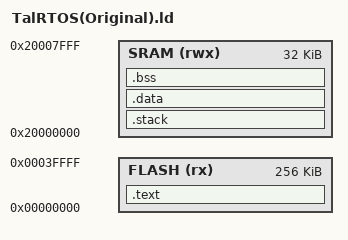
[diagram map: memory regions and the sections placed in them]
/* Linker script to configure memory regions. 
 * Need modifying for a specific board. 
 *   FLASH.ORIGIN: starting address of flash
 *   FLASH.LENGTH: length of flash
 *   RAM.ORIGIN: starting address of RAM bank 0
 *   RAM.LENGTH: length of RAM bank 0
 */
MEMORY
{
    FLASH (rx) : ORIGIN = 0x00000000, LENGTH = 256K
    SRAM (rwx) : ORIGIN = 0x20000000, LENGTH = 32K
}

/* The size of the stack used by the application. NOTE: you need to adjust  */
STACK_SIZE = 1024;

/* The size of the heap used by the application. NOTE: you need to adjust   */
HEAP_SIZE = 0;

SECTIONS
{
    .text :
    {
        _text = .;
        KEEP(*(.isr_vector))
        *(.text*)
        *(.rodata*)
        _etext = .;
    } > FLASH

	.stack : {
        __stack_start__ = .;
        . = . + STACK_SIZE;
        . = ALIGN(4);
        __stack_end__ = .;
    } > SRAM

    .data : AT(ADDR(.text) + SIZEOF(.text))
    {
        _data = .;
        _ldata = LOADADDR (.data);
        *(vtable)
        *(.data*)
        _edata = .;
    } > SRAM

    .bss :
    {
        _bss = .;
        *(.bss*)
        *(COMMON)
        _ebss = .;
    } > SRAM
}
